# MIMXRT1064 register map
Vendor: nxp.com; File version: 1.0
CPU: CM7 r0p1, little endian, MPU, FPU, VTOR, 4 interrupt priority bits
Registers are 32-bit, read-write, reset 0x0 unless marked. A register's access mark holds for its fields unless they carry their own. Offsets are from the block's base; [hi:lo] are bit positions; {n}, {i} and the like mark numbered series.

## LPSPI1 — LPSPI
Base 0x40394000
Same registers: LPSPI2 0x40398000, LPSPI3 0x4039C000, LPSPI4 0x403A0000
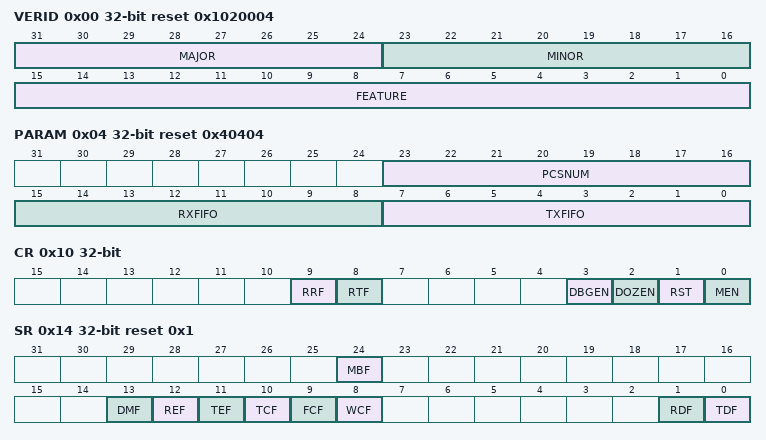
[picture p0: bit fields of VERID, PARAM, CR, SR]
0x00 VERID ro reset 0x1020004 — Version ID Register
  [31:24] MAJOR — Major Version Number
  [23:16] MINOR — Minor Version Number
  [15:0] FEATURE — Module Identification Number
    4=Standard feature set supporting a 32-bit shift register
0x04 PARAM ro reset 0x40404 — Parameter Register
  [23:16] PCSNUM — PCS Number
  [15:8] RXFIFO — Receive FIFO Size
  [7:0] TXFIFO — Transmit FIFO Size
0x10 CR — Control Register
  [9] RRF wo — Reset Receive FIFO
    0=No effect; 1=Receive FIFO is reset
  [8] RTF wo — Reset Transmit FIFO
    0=No effect; 1=Transmit FIFO is reset
  [3] DBGEN — Debug Enable
    0=Module is disabled in debug mode; 1=Module is enabled in debug mode
  [2] DOZEN — Doze mode enable
    0=Module is enabled in Doze mode; 1=Module is disabled in Doze mode
  [1] RST — Software Reset
    0=Module is not reset; 1=Module is reset
  [0] MEN — Module Enable
    0=Module is disabled; 1=Module is enabled
0x14 SR reset 0x1 — Status Register
  [24] MBF ro — Module Busy Flag
    0=LPSPI is idle; 1=LPSPI is busy
  [13] DMF write-1-clears — Data Match Flag
    0=Have not received matching data; 1=Have received matching data
  [12] REF write-1-clears — Receive Error Flag
    0=Receive FIFO has not overflowed; 1=Receive FIFO has overflowed
  [11] TEF write-1-clears — Transmit Error Flag
    0=Transmit FIFO underrun has not occurred; 1=Transmit FIFO underrun has occurred
  [10] TCF write-1-clears — Transfer Complete Flag
    0=All transfers have not completed; 1=All transfers have completed
  [9] FCF write-1-clears — Frame Complete Flag
    0=Frame transfer has not completed; 1=Frame transfer has completed
  [8] WCF write-1-clears — Word Complete Flag
    0=Transfer of a received word has not yet completed; 1=Transfer of a received word has completed
  [1] RDF ro — Receive Data Flag
    0=Receive Data is not ready; 1=Receive data is ready
  [0] TDF ro — Transmit Data Flag
    0=Transmit data not requested; 1=Transmit data is requested
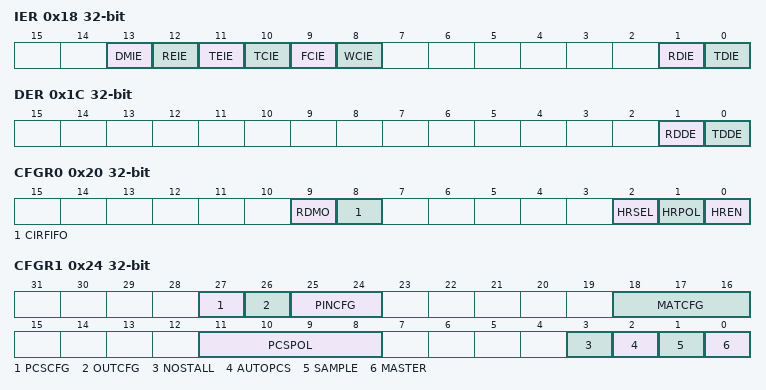
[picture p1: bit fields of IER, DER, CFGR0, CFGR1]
0x18 IER — Interrupt Enable Register
  [all] fields
    0=Disabled; 1=Enabled
  [13] DMIE — Data Match Interrupt Enable
  [12] REIE — Receive Error Interrupt Enable
  [11] TEIE — Transmit Error Interrupt Enable
  [10] TCIE — Transfer Complete Interrupt Enable
  [9] FCIE — Frame Complete Interrupt Enable
  [8] WCIE — Word Complete Interrupt Enable
  [1] RDIE — Receive Data Interrupt Enable
  [0] TDIE — Transmit Data Interrupt Enable
0x1C DER — DMA Enable Register
  [1] RDDE — Receive Data DMA Enable
    0=DMA request is disabled; 1=DMA request is enabled
  [0] TDDE — Transmit Data DMA Enable
    0=DMA request is disabled; 1=DMA request is enabled
0x20 CFGR0 — Configuration Register 0
  [9] RDMO — Receive Data Match Only
    0=Received data is stored in the receive FIFO as in normal operations; 1=Received data is discarded unless the Data Match Flag (DMF) is set
  [8] CIRFIFO — Circular FIFO Enable
    0=Circular FIFO is disabled; 1=Circular FIFO is enabled
  [2] HRSEL — Host Request Select
    0=Host request input is the LPSPI_HREQ pin; 1=Host request input is the input trigger
  [1] HRPOL — Host Request Polarity
    0=Active low; 1=Active high
  [0] HREN — Host Request Enable
    0=Host request is disabled; 1=Host request is enabled
0x24 CFGR1 — Configuration Register 1
  [27] PCSCFG — Peripheral Chip Select Configuration
    0=PCS[3:2] are enabled; 1=PCS[3:2] are disabled
  [26] OUTCFG — Output Config
    0=Output data retains last value when chip select is negated; 1=Output data is tristated when chip select is negated
  [25:24] PINCFG — Pin Configuration
    0=SIN is used for input data and SOUT is used for output data; 1=SIN is used for both input and output data; 2=SOUT is used for both input and output data; 3=SOUT is used for input data and SIN is used for output data
  [18:16] MATCFG — Match Configuration
    0=Match is disabled; 2=010b - Match is enabled, if 1st data word equals MATCH0 OR MATCH1, i.e., (1st data word = MATCH0 + MATCH1); 3=011b - Match is enabled, if any data word equals MATCH0 OR MATCH1, i.e., (any data word = MATCH0 + MATCH1); 4=100b - Match is enabled, if 1st data word equals MATCH0 AND 2nd data word equals MATCH1, i.e., [(1st data word = MATCH0) * (2nd data word = MATCH1)]; 5=101b - Match is enabled, if any data word equals MATCH0 AND the next data word equals MATCH1, i.e., [(any data word = MATCH0) * (next data word = MATCH1)]; 6=110b - Match is enabled, if (1st data word AND MATCH1) equals (MATCH0 AND MATCH1), i.e., [(1st data word * MATCH1) = (MATCH0 * MATCH1)]; 7=111b - Match is enabled, if (any data word AND MATCH1) equals (MATCH0 AND MATCH1), i.e., [(any data word * MATCH1) = (MATCH0 * MATCH1)]
  [11:8] PCSPOL — Peripheral Chip Select Polarity
    0=The Peripheral Chip Select pin PCSx is active low; 1=The Peripheral Chip Select pin PCSx is active high
  [3] NOSTALL
    0=Transfers will stall when the transmit FIFO is empty or the receive FIFO is full; 1=Transfers will not stall, allowing transmit FIFO underruns or receive FIFO overruns to occur
  [2] AUTOPCS — Automatic PCS
    0=Automatic PCS generation is disabled; 1=Automatic PCS generation is enabled
  [1] SAMPLE — Sample Point
    0=Input data is sampled on SCK edge; 1=Input data is sampled on delayed SCK edge
  [0] MASTER — Master Mode
    0=Slave mode; 1=Master mode
0x30 DMR0 — Data Match Register 0
  [31:0] MATCH0 — Match 0 Value
0x34 DMR1 — Data Match Register 1
  [31:0] MATCH1 — Match 1 Value
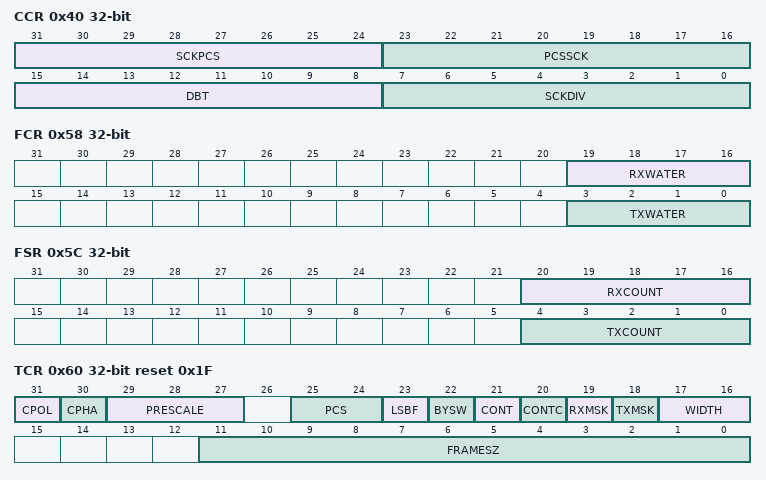
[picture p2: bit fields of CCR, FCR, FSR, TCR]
0x40 CCR — Clock Configuration Register
  [31:24] SCKPCS — SCK-to-PCS Delay
  [23:16] PCSSCK — PCS-to-SCK Delay
  [15:8] DBT — Delay Between Transfers
  [7:0] SCKDIV — SCK Divider
0x58 FCR — FIFO Control Register
  [19:16] RXWATER — Receive FIFO Watermark
  [3:0] TXWATER — Transmit FIFO Watermark
0x5C FSR ro — FIFO Status Register
  [20:16] RXCOUNT — Receive FIFO Count
  [4:0] TXCOUNT — Transmit FIFO Count
0x60 TCR reset 0x1F — Transmit Command Register
  [31] CPOL — Clock Polarity
    0=The inactive state value of SCK is low; 1=The inactive state value of SCK is high
  [30] CPHA — Clock Phase
    0=Data is captured on the leading edge of SCK and changed on the following edge of SCK; 1=Data is changed on the leading edge of SCK and captured on the following edge of SCK
  [29:27] PRESCALE — Prescaler Value
    0=Divide by 1; 1=Divide by 2; 2=Divide by 4; 3=Divide by 8; 4=Divide by 16; 5=Divide by 32; 6=Divide by 64; 7=Divide by 128
  [25:24] PCS — Peripheral Chip Select
    {v}=Transfer using LPSPI_PCS[{v}] (v=0..3)
  [23] LSBF — LSB First
    0=Data is transferred MSB first; 1=Data is transferred LSB first
  [22] BYSW — Byte Swap
    0=Byte swap is disabled; 1=Byte swap is enabled
  [21] CONT — Continuous Transfer
    0=Continuous transfer is disabled; 1=Continuous transfer is enabled
  [20] CONTC — Continuing Command
    0=Command word for start of new transfer; 1=Command word for continuing transfer
  [19] RXMSK — Receive Data Mask
    0=Normal transfer; 1=Receive data is masked
  [18] TXMSK — Transmit Data Mask
    0=Normal transfer; 1=Mask transmit data
  [17:16] WIDTH — Transfer Width
    0=1 bit transfer; 1=2 bit transfer; 2=4 bit transfer
  [11:0] FRAMESZ — Frame Size
0x64 TDR wo — Transmit Data Register
  [31:0] DATA — Transmit Data
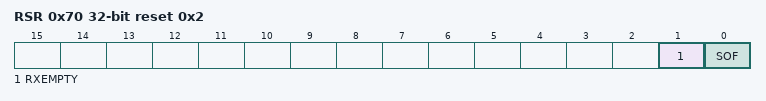
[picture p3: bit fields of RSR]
0x70 RSR ro reset 0x2 — Receive Status Register
  [1] RXEMPTY — RX FIFO Empty
    0=RX FIFO is not empty; 1=RX FIFO is empty
  [0] SOF — Start Of Frame
    0=Subsequent data word received after LPSPI_PCS assertion; 1=First data word received after LPSPI_PCS assertion
0x74 RDR ro — Receive Data Register
  [31:0] DATA — Receive Data
